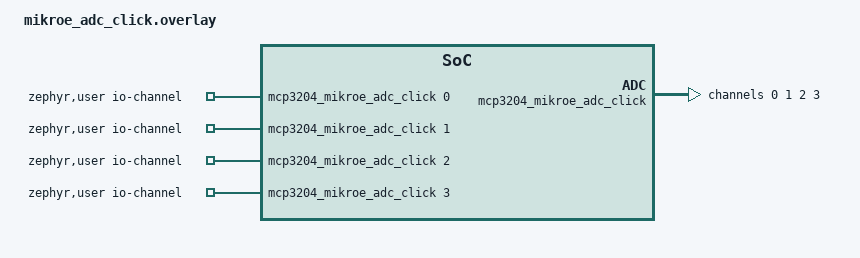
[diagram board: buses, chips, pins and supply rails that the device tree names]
/*
 * SPDX-License-Identifier: Apache-2.0
 *
 * Copyright (c) 2023 Vestas Wind Systems A/S
 */

/ {
	zephyr,user {
		io-channels = <&mcp3204_mikroe_adc_click 0>,
			      <&mcp3204_mikroe_adc_click 1>,
			      <&mcp3204_mikroe_adc_click 2>,
			      <&mcp3204_mikroe_adc_click 3>;
	};
};

&mcp3204_mikroe_adc_click {
	#address-cells = <1>;
	#size-cells = <0>;

	channel@0 {
		reg = <0>;
		zephyr,gain = "ADC_GAIN_1";
		zephyr,reference = "ADC_REF_EXTERNAL0";
		zephyr,acquisition-time = <ADC_ACQ_TIME_DEFAULT>;
		zephyr,vref-mv = <3300>;
		zephyr,resolution = <12>;
	};

	channel@1 {
		reg = <1>;
		zephyr,gain = "ADC_GAIN_1";
		zephyr,reference = "ADC_REF_EXTERNAL0";
		zephyr,acquisition-time = <ADC_ACQ_TIME_DEFAULT>;
		zephyr,vref-mv = <3300>;
		zephyr,resolution = <12>;
	};

	channel@2 {
		reg = <2>;
		zephyr,gain = "ADC_GAIN_1";
		zephyr,reference = "ADC_REF_EXTERNAL0";
		zephyr,acquisition-time = <ADC_ACQ_TIME_DEFAULT>;
		zephyr,vref-mv = <3300>;
		zephyr,resolution = <12>;
	};

	channel@3 {
		reg = <3>;
		zephyr,gain = "ADC_GAIN_1";
		zephyr,reference = "ADC_REF_EXTERNAL0";
		zephyr,acquisition-time = <ADC_ACQ_TIME_DEFAULT>;
		zephyr,vref-mv = <3300>;
		zephyr,resolution = <12>;
	};
};
